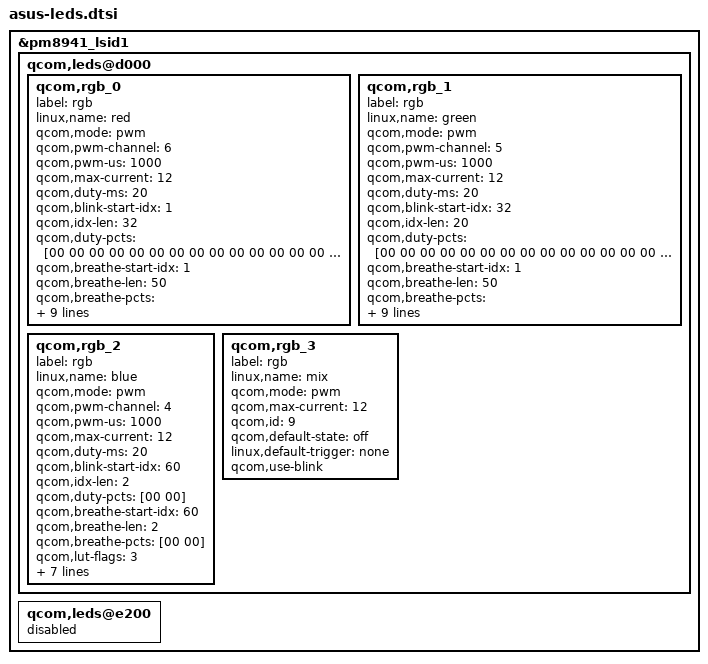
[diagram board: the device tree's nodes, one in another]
/*
 * Copyright (c) 2012-2013, The Linux Foundation. All rights reserved.
 *
 * This program is free software; you can redistribute it and/or modify
 * it under the terms of the GNU General Public License version 2 and
 * only version 2 as published by the Free Software Foundation.
 *
 * This program is distributed in the hope that it will be useful,
 * but WITHOUT ANY WARRANTY; without even the implied warranty of
 * MERCHANTABILITY or FITNESS FOR A PARTICULAR PURPOSE.  See the
 * GNU General Public License for more details.
 */

#include "../msm8974-leds.dtsi"

&pm8941_lsid1 {
	qcom,leds@d000 {
		status = "okay";
		qcom,rgb_0 {
			label = "rgb";
			linux,name = "red";
			qcom,mode = "pwm";
			qcom,pwm-channel = <6>;
			qcom,pwm-us = <1000>;
			qcom,max-current = <12>;
			qcom,duty-ms = <20>;

			qcom,blink-start-idx = <1>;
			qcom,idx-len = <32>;
			qcom,duty-pcts = [00 00 00 00 00 00 00 00 00 00
					  00 00 00 00 00 00 00 00 00 00
					  00 00 00 00 00 00 00 00 00 00 
					  00 60 ];

			qcom,breathe-start-idx = <1>;
			qcom,breathe-len = <50>;
			qcom,breathe-pcts = [00 00 00 00 01 02 03 04 05 06
					     07 08 09 0A 0C 0E 10 12 14 18
					     1C 20 25 2A 32 3C 32 2A 25 20
					     1C 18 14 12 10 0E 0C 0A 09 08
					     07 06 05 04 03 02 01 00 00 00];

			qcom,lut-flags = <3>;
			qcom,pause-lo = <0>;
			qcom,pause-hi = <1>;
			qcom,ramp-step-ms = <125>;
			qcom,default-state = "off";
			//qcom,turn-off-delay-ms = <3000>;
			qcom,id = <3>;
			linux,default-trigger =	"none";
			qcom,use-blink;
		};

		qcom,rgb_1 {
			label = "rgb";
			linux,name = "green";
			qcom,mode = "pwm";
			qcom,pwm-channel = <5>;
			qcom,pwm-us = <1000>;
			qcom,max-current = <12>;
			qcom,duty-ms = <20>;

			qcom,blink-start-idx = <32>;
			qcom,idx-len = <20>;
			qcom,duty-pcts = [00 00 00 00 00 00 00 00 00 00
					  00 00 00 00 00 00 00 00 00 60];

			qcom,breathe-start-idx = <1>;
			qcom,breathe-len = <50>;
			qcom,breathe-pcts = [00 00 00 00 01 02 03 04 05 06
					     07 08 09 0A 0C 0E 10 12 14 18
					     1C 20 25 2A 32 3C 32 2A 25 20
					     1C 18 14 12 10 0E 0C 0A 09 08
					     07 06 05 04 03 02 01 00 00 00];

			qcom,lut-flags = <3>;
			qcom,pause-lo = <0>;
			qcom,pause-hi = <1>;
			qcom,ramp-step-ms = <125>;
			qcom,default-state = "off";
			qcom,id = <4>;
			linux,default-trigger = "none";
			qcom,use-blink;
		};

		qcom,rgb_2 {
			label = "rgb";
			linux,name = "blue";
			qcom,mode = "pwm";
			qcom,pwm-channel = <4>;
			qcom,pwm-us = <1000>;
			qcom,max-current = <12>;
			qcom,duty-ms = <20>;
			qcom,blink-start-idx = <60>;
			qcom,idx-len = <2>;
			qcom,duty-pcts = [00 00];
			qcom,breathe-start-idx = <60>;
			qcom,breathe-len = <2>;
			qcom,breathe-pcts = [00 00];
			qcom,lut-flags = <3>;
			qcom,pause-lo = <0>;
			qcom,pause-hi = <1>;
			qcom,ramp-step-ms = <125>;
			qcom,default-state = "off";
			qcom,id = <5>;
			linux,default-trigger = "none";
			qcom,use-blink;
		};

// ASUS_BSP Deeo : add for new kobject +++
		qcom,rgb_3 {
			label = "rgb";
			linux,name = "mix";
			qcom,mode = "pwm";
			qcom,max-current = <12>;
			qcom,id = <9>;
			qcom,default-state = "off";
			linux,default-trigger = "none";
			qcom,use-blink;
		};
// ASUS_BSP Deeo : add for new kobject ---
	};
	qcom,leds@e200 {
		status = "disable"; //ASUS_BSP Deeo : disable kpbl
	};
};
